# RK3399-AP register map
File version: 1
CPU: CA7 r0p1, little endian, MPU, FPU, I-cache, D-cache, VTOR, 4 interrupt priority bits, 0 interrupts
Registers are 32-bit, read-write, reset 0x0 unless marked. A register's access mark holds for its fields unless they carry their own. Offsets are from the block's base; [hi:lo] are bit positions; <NAME> marks a mode.

## GMAC (part 1 of 2)
Base 0xFE300000
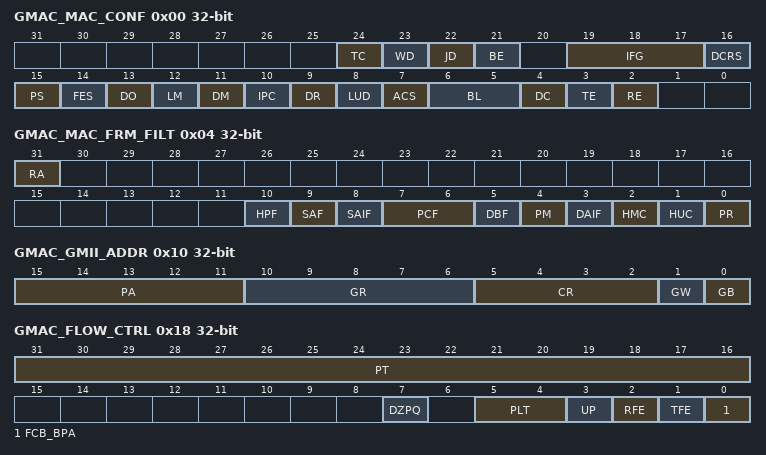
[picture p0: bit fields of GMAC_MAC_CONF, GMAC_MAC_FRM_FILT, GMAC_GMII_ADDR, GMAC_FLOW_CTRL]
0x00 GMAC_MAC_CONF — MAC Configuration Register
  [24] TC — Transmit Configuration in RGMII When set, this bit enables the transmission of duplex mode, link speed, and link up/down information to the PHY in the RGMII ports. When this bit is reset, no such information is driven to the PHY.
  [23] WD — Watchdog Disable When this bit is set, the GMAC disables the watchdog timer on the receiver, and can receive frames of up to 16,384 bytes. When this bit is reset, the GMAC allows no more than 2,048 bytes (10,240 if JE is set high) of the frame being received and cuts off any bytes received after that.
  [22] JD — Jabber Disable When this bit is set, the GMAC disables the jabber timer on the transmitter, and can transfer frames of up to 16,384 bytes. When this bit is reset, the GMAC cuts off the transmitter if the application sends out more than 2,048 bytes of data (10,240 if JE is set high) during transmission.
  [21] BE — Frame Burst Enable When this bit is set, the GMAC allows frame bursting during transmission in GMII Half-Duplex mode.
  [19:17] IFG — Inter-Frame Gap These bits control the minimum IFG between frames during transmission. 3\'b000: 96 bit times 3\'b001: 88 bit times 3\'b010: 80 bit times ... 3\'b111: 40 bit times
  [16] DCRS — Disable Carrier Sense During Transmission When set high, this bit makes the MAC transmitter ignore the (G)MII CRS signal during frame transmission in Half-Duplex mode. This request results in no errors generated due to Loss of Carrier or No Carrier during such transmission. When this bit is low, the MAC transmitter generates such errors due to Carrier Sense and will even abort the transmissions.
  [15] PS — Port Select Selects between GMII and MII: 1\'b0: GMII (1000 Mbps) 1\'b1: MII (10/100 Mbps)
  [14] FES — Speed Indicates the speed in Fast Ethernet (MII) mode: 1\'b0: 10 Mbps 1\'b1: 100 Mbps
  [13] DO — Disable Receive Own When this bit is set, the GMAC disables the reception of frames when the gmii_txen_o is asserted in Half-Duplex mode. When this bit is reset, the GMAC receives all packets that are given by the PHY while transmitting.
  [12] LM — Loopback Mode When this bit is set, the GMAC operates in loopback mode at GMII/MII. The (G)MII Receive clock input (clk_rx_i) is required for the loopback to work properly, as the Transmit clock is not looped-back internally.
  [11] DM — Duplex Mode When this bit is set, the GMAC operates in a Full-Duplex mode where it can transmit and receive simultaneously. This bit is RO with default value of 1\'b1 in Full-Duplex-only configuration.
  [10] IPC — Checksum Offload When this bit is set, the GMAC calculates the 16-bit one\'s complement of the one\'s complement sum of all received Ethernet frame payloads. It also checks whether the IPv4 Header checksum (assumed to be bytes 25-26 or 29-30 (VLAN-tagged) of the received Ethernet frame) is correct for the received frame and gives the status in the receive status word. The GMAC core also appends the 16-bit checksum calculated for the IP header datagram payload (bytes after the IPv4 header) and appends it to the Ethernet frame transferred to the application (when Type 2 COE is deselected). When this bit is reset, this function is disabled. When Type 2 COE is selected, this bit, when set, enables IPv4 checksum checking for received frame payloads TCP/UDP/ICMP headers. When this bit is reset, the COE function in the receiver is disabled and the corresponding PCE and IP HCE status bits are always cleared.
  [9] DR — Disable Retry When this bit is set, the GMAC will attempt only 1 transmission. When a collision occurs on the GMII/MII, the GMAC will ignore the current frame transmission and report a Frame Abort with excessive collision error in the transmit frame status. When this bit is reset, the GMAC will attempt retries based on the settings of BL.
  [8] LUD — Link Up/Down Indicates whether the link is up or down during the transmission of configuration in RGMII interface: 1\'b0: Link Down 1\'b1: Link Up
  [7] ACS — Automatic Pad/CRC Stripping When this bit is set, the GMAC strips the Pad/FCS field on incoming frames only if the length\'s field value is less than or equal to 1,500 bytes. All received frames with length field greater than or equal to 1,501 bytes are passed to the application without stripping the Pad/FCS field. When this bit is reset, the GMAC will pass all incoming frames to the Host unmodified.
  [6:5] BL — Back-Off Limit The Back-Off limit determines the random integer number (r) of slot time delays (4,096 bit times for 1000 Mbps and 512 bit times for 10/100 Mbps) the GMAC waits before rescheduling a transmission attempt during retries after a collision. This bit is applicable only to Half-Duplex mode and is reserved (RO) in Full- Duplex-only configuration. 2\'b00: k = min (n, 10) 2\'b01: k = min (n, 8) 2\'b10: k = min (n, 4) 2\'b11: k = min (n, 1), Where n = retransmission attempt. The random integer r takes the value in the range 0 = r < 2^k
  [4] DC — Deferral Check When this bit is set, the deferral check function is enabled in the GMAC. The GMAC will issue a Frame Abort status, along with the excessive deferral error bit set in the transmit frame status when the transmission state machine is deferred for more than 24,288 bit times in 10/100-Mbps mode. If the Core is configured for 1000 Mbps operation, the threshold for deferral is 155,680 bits times. Deferral begins when the transmitter is ready to transmit, but is prevented because of an active CRS (carrier sense) signal on the GMII/MII. Defer time is not cumulative. If the transmitter defers for 10,000 bit times, then transmits, collides, backs off, and then has to defer again after completion of back-off, the deferral timer resets to 0 and restarts. When this bit is reset, the deferral check function is disabled and the GMAC defers until the CRS signal goes inactive.
  [3] TE — Transmitter Enable When this bit is set, the transmission state machine of the GMAC is enabled for transmission on the GMII/MII. When this bit is reset, the GMAC transmit state machine is disabled after the completion of the transmission of the current frame, and will not transmit any further frames.
  [2] RE — Receiver Enable When this bit is set, the receiver state machine of the GMAC is enabled for receiving frames from the GMII/MII. When this bit is reset, the GMAC receive state machine is disabled after the completion of the reception of the current frame, and will not receive any further frames from the GMII/MII.
0x04 GMAC_MAC_FRM_FILT — MAC Frame Filter
  [31] RA — Receive All When this bit is set, the GMAC Receiver module passes to the Application all frames received irrespective of whether they pass the address filter. The result of the SA/DA filtering is updated (pass or fail) in the corresponding bits in the Receive Status Word. When this bit is reset, the Receiver module passes to the Application only those frames that pass the SA/DA address filter.
  [10] HPF — Hash or Perfect Filter When set, this bit configures the address filter to pass a frame if it matches either the perfect filtering or the hash filtering as set by HMC or HUC bits. When low and if the HUC/HMC bit is set, the frame is passed only if it matches the Hash filter.
  [9] SAF — Source Address Filter Enable The GMAC core compares the SA field of the received frames with the values programmed in the enabled SA registers. If the comparison matches, then the SAMatch bit of RxStatus Word is set high. When this bit is set high and the SA filter fails, the GMAC drops the frame. When this bit is reset, then the GMAC Core forwards the received frame to the application and with the updated SA Match bit of the RxStatus depending on the SA address comparison.
  [8] SAIF — SA Inverse Filtering When this bit is set, the Address Check block operates in inverse filtering mode for the SA address comparison. The frames whose SA matches the SA registers will be marked as failing the SA Address filter. When this bit is reset, frames whose SA does not match the SA registers will be marked as failing the SA Address filter.
  [7:6] PCF — Pass Control Frames These bits control the forwarding of all control frames (including unicast and multicast PAUSE frames). Note that the processing of PAUSE control frames depends only on RFE of Register GMAC_FLOW_CTRL[2]. 2\'b00: GMAC filters all control frames from reaching the application. 2\'b01: GMAC forwards all control frames except PAUSE control frames to application even if they fail the Address filter. 2\'b10: GMAC forwards all control frames to application even if they fail the Address Filter. 2\'b11: GMAC forwards control frames that pass the Address Filter.
  [5] DBF — Disable Broadcast Frames When this bit is set, the AFM module filters all incoming broadcast frames. When this bit is reset, the AFM module passes all received broadcast frames.
  [4] PM — Pass All Multicast When set, this bit indicates that all received frames with a multicast destination address (first bit in the destination address field is \'1\') are passed. When reset, filtering of multicast frame depends on HMC bit.
  [3] DAIF — DA Inverse Filtering When this bit is set, the Address Check block operates in inverse filtering mode for the DA address comparison for both unicast and multicast frames. When reset, normal filtering of frames is performed.
  [2] HMC — Hash Multicast When set, MAC performs destination address filtering of received multicast frames according to the hash table. When reset, the MAC performs a perfect destination address filtering for multicast frames, that is, it compares the DA field with the values programmed in DA registers.
  [1] HUC — Hash Unicast When set, MAC performs destination address filtering of unicast frames according to the hash table. When reset, the MAC performs a perfect destination address filtering for unicast frames, that is, it compares the DA field with the values programmed in DA registers.
  [0] PR — Promiscuous Mode When this bit is set, the Address Filter module passes all incoming frames regardless of its destination or source address. The SA/DA Filter Fails status bits of the Receive Status Word will always be cleared when PR is set.
0x08 GMAC_HASH_TAB_HI — Hash Table High Register
  [31:0] HTH — Hash Table High This field contains the upper 32 bits of Hash table
0x0C GMAC_HASH_TAB_LO — Hash Table Low Register
  [31:0] HTL — Hash Table Low This field contains the lower 32 bits of Hash table
0x10 GMAC_GMII_ADDR — GMII Address Register
  [15:11] PA — Physical Layer Address This field tells which of the 32 possible PHY devices are being accessed
  [10:6] GR — GMII Register These bits select the desired GMII register in the selected PHY device
  [5:2] CR — APB Clock Range The APB Clock Range selection determines the frequency of the MDC clock as per the pclk_gmac frequency used in your design. The suggested range of pclk_gmac frequency applicable for each value below (when Bit[5] = 0) ensures that the MDC clock is approximately between the frequency range 1.0 MHz - 2.5 MHz. 0000 60-100 MHz pclk_gmac/42 0001 100-150 MHz pclk_gmac/62 0010 20-35 MHz pclk_gmac/16 0011 35-60 MHz pclk_gmac/26 0100 150-250 MHz pclk_gmac/102 0101 250-300 MHz pclk_gmac/124 0110, 0111 Reserved When bit 5 is set, you can achieve MDC clock of frequency higher than the IEEE802.3 specified frequency limit of 2.5 MHz and program a clock divider of lower value. For example, when pclk_gmac is of frequency 100 MHz and you program these bits as "1010", then the resultant MDC clock will be of 12.5 MHz which is outside the limit of IEEE 802.3 specified range. Please program the values given below only if the interfacing chips supports faster MDC clocks. 1000 pclk_gmac/4 1001 pclk_gmac/6 1010 pclk_gmac/8 1011 pclk_gmac/10 1100 pclk_gmac/12 1101 pclk_gmac/14 1110 pclk_gmac/16 1111 pclk_gmac/18
  [1] GW — GMII Write When set, this bit tells the PHY that this will be a Write operation using register GMAC_GMII_DATA. If this bit is not set, this will be a Read operation, placing the data in register GMAC_GMII_DATA.
  [0] GB write-1-clears — GMII Busy This bit should read a logic 0 before writing to Register GMII_ADDR and Register GMII_DATA. This bit must also be set to 0 during a Write to Register GMII_ADDR. During a PHY register access, this bit will be set to 1\'b1 by the Application to indicate that a Read or Write access is in progress. Register GMII_DATA (GMII Data) should be kept valid until this bit is cleared by the GMAC during a PHY Write operation. The Register GMII_DATA is invalid until this bit is cleared by the GMAC during a PHY Read operation. The Register GMII_ADDR (GMII Address) should not be written to until this bit is cleared.
0x14 GMAC_GMII_DATA — GMII Data Register
  [15:0] GD — GMII Data This contains the 16-bit data value read from the PHY after a Management Read operation or the 16-bit data value to be written to the PHY before a Management Write operation.
0x18 GMAC_FLOW_CTRL — Flow Control Register
  [31:16] PT — Pause Time This field holds the value to be used in the Pause Time field in the transmit control frame. If the Pause Time bits is configured to be double-synchronized to the (G)MII clock domain, then consecutive writes to this register should be performed only after at least 4 clock cycles in the destination clock domain.
  [7] DZPQ — Disable Zero-Quanta Pause When set, this bit disables the automatic generation of Zero- Quanta Pause Control frames on the de-assertion of the flow- control signal from the FIFO layer (MTL or external sideband flow control signal sbd_flowctrl_i/mti_flowctrl_i). When this bit is reset, normal operation with automatic Zero- Quanta Pause Control frame generation is enabled.
  [5:4] PLT — Pause Low Threshold This field configures the threshold of the PAUSE timer at which the input flow control signal mti_flowctrl_i (or sbd_flowctrl_i) is checked for automatic retransmission of PAUSE Frame. The threshold values should be always less than the Pause Time configured in Bits[31:16]. For example, if PT = 100H (256 slot- times), and PLT = 01, then a second PAUSE frame is automatically transmitted if the mti_flowctrl_i signal is asserted at 228 (256-28) slot-times after the first PAUSE frame is transmitted. 00 Pause time minus 4 slot times 01 Pause time minus 28 slot times 10 Pause time minus 144 slot times 11 Pause time minus 256 slot times Slot time is defined as time taken to transmit 512 bits (64 bytes) on the GMII/MII interface.
  [3] UP — Unicast Pause Frame Detect When this bit is set, the GMAC will detect the Pause frames with the station\'s unicast address specified in MAC Address0 High Register and MAC Address0 Low Register, in addition to the detecting Pause frames with the unique multicast address. When this bit is reset, the GMAC will detect only a Pause frame with the unique multicast address specified in the 802.3x standard.
  [2] RFE — Receive Flow Control Enable When this bit is set, the GMAC will decode the received Pause frame and disable its transmitter for a specified (Pause Time) time. When this bit is reset, the decode function of the Pause frame is disabled.
  [1] TFE — Transmit Flow Control Enable In Full-Duplex mode, when this bit is set, the GMAC enables the flow control operation to transmit Pause frames. When this bit is reset, the flow control operation in the GMAC is disabled, and the GMAC will not transmit any Pause frames. In Half-Duplex mode, when this bit is set, the GMAC enables the back-pressure operation. When this bit is reset, the backpressure feature is disabled.
  [0] FCB_BPA — Flow Control Busy/Backpressure Activate This bit initiates a Pause Control frame in Full-Duplex mode and activates the backpressure function in Half-Duplex mode if TFE bit is set. In Full-Duplex mode, this bit should be read as 1\'b0 before writing to the register GMAC_FLOW_CTRL. To initiate a pause control frame, the application must set this bit to 1\'b1. During a transfer of the control frame, this bit will continue to be set to signify that a frame transmission is in progress. After the completion of Pause control frame transmission, the GMAC will reset this bit to 1\'b0. The register GMAC_FLOW_CTRL should not be written to until this bit is cleared. In Half-Duplex mode, when this bit is set (and TFE is set), then backpressure is asserted by the GMAC Core. During backpressure, when the GMAC receives a new frame, the transmitter starts sending a JAM pattern resulting in a collision. This control register bit is logically OR\'ed with the mti_flowctrl_i input signal for the backpressure function.
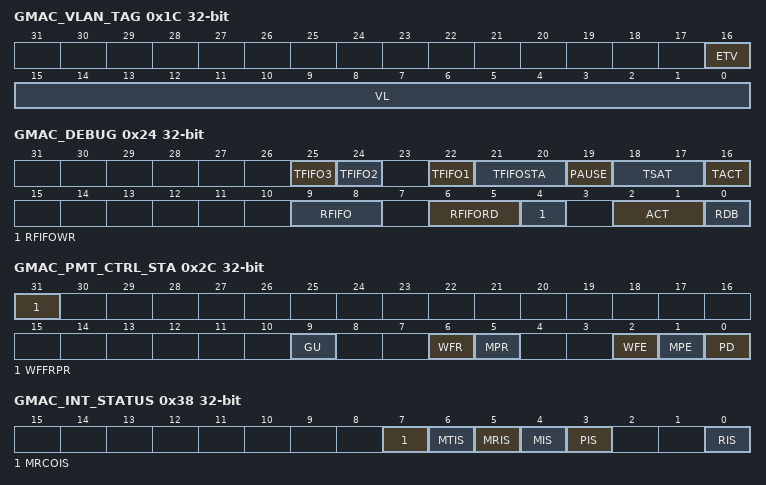
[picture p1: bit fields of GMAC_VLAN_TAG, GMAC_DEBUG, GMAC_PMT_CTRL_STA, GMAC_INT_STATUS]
0x1C GMAC_VLAN_TAG — VLAN Tag Register
  [16] ETV — Enable 12-Bit VLAN Tag Comparison When this bit is set, a 12-bit VLAN identifier, rather than the complete 16-bit VLAN tag, is used for comparison and filtering. Bits[11:0] of the VLAN tag are compared with the corresponding field in the received VLAN-tagged frame. When this bit is reset, all 16 bits of the received VLAN frame\'s fifteenth and sixteenth bytes are used for comparison.
  [15:0] VL — VLAN Tag Identifier for Receive Frames This contains the 802.1Q VLAN tag to identify VLAN frames, and is compared to the fifteenth and sixteenth bytes of the frames being received for VLAN frames. Bits[15:13] are the User Priority, Bit[12] is the Canonical Format Indicator (CFI) and bits[11:0] are the VLAN tag\'s VLAN Identifier (VID) field. When the ETV bit is set, only the VID (Bits[11:0]) is used for comparison. If VL (VL[11:0] if ETV is set) is all zeros, the GMAC does not check the fifteenth and sixteenth bytes for VLAN tag comparison, and declares all frames with a Type field value of 0x8100 to be VLAN frames.
0x24 GMAC_DEBUG — Debug register
  [25] TFIFO3 — When high, it indicates that the MTL TxStatus FIFO is full and hence the MTL will not be accepting any more frames for transmission.
  [24] TFIFO2 — When high, it indicates that the MTL TxFIFO is not empty and has some data left for transmission.
  [22] TFIFO1 — When high, it indicates that the MTL TxFIFO Write Controller is active and transferring data to the TxFIFO.
  [21:20] TFIFOSTA — This indicates the state of the TxFIFO read Controller: 2\'b00: IDLE state 2\'b01: READ state (transferring data to MAC transmitter) 2\'b10: Waiting for TxStatus from MAC transmitter 2\'b11: Writing the received TxStatus or flushing the TxFIFO
  [19] PAUSE — When high, it indicates that the MAC transmitter is in PAUSE condition (in full-duplex only) and hence will not schedule any frame for transmission
  [18:17] TSAT — This indicates the state of the MAC Transmit Frame Controller module: 2\'b00: IDLE 2\'b01: Waiting for Status of previous frame or IFG/backoff period to be over 2\'b10: Generating and transmitting a PAUSE control frame (in full duplex mode) 2\'b11: Transferring input frame for transmission
  [16] TACT — When high, it indicates that the MAC GMII/MII transmit protocol engine is actively transmitting data and not in IDLE state.
  [9:8] RFIFO — This gives the status of the RxFIFO Fill-level: 2\'b00: RxFIFO Empty 2\'b01: RxFIFO fill-level below flow-control de-activate threshold 2\'b10: RxFIFO fill-level above flow-control activate threshold 2\'b11: RxFIFO Full
  [6:5] RFIFORD — It gives the state of the RxFIFO read Controller: 2\'b00: IDLE state 2\'b01: Reading frame data 2\'b10: Reading frame status (or time-stamp) 2\'b11: Flushing the frame data and Status
  [4] RFIFOWR — When high, it indicates that the MTL RxFIFO Write Controller is active and transferring a received frame to the FIFO.
  [2:1] ACT — When high, it indicates the active state of the small FIFO Read and Write controllers respectively of the MAC receive Frame Controller module
  [0] RDB — When high, it indicates that the MAC GMII/MII receive protocol engine is actively receiving data and not in IDLE state.
0x2C GMAC_PMT_CTRL_STA access per field — PMT Control and Status Register
  [31] WFFRPR rw write-1-clears — Wake-Up Frame Filter Register Pointer Reset When set, resets the Remote Wake-up Frame Filter register pointer to 3\'b000. It is automatically cleared after 1 clock cycle.
  [9] GU rw — Global Unicast When set, enables any unicast packet filtered by the GMAC (DAF) address recognition to be a wake-up frame.
  [6] WFR ro read-clears — Wake-Up Frame Received When set, this bit indicates the power management event was generated due to reception of a wake-up frame. This bit is cleared by a read into this register.
  [5] MPR ro read-clears — Magic Packet Received When set, this bit indicates the power management event was generated by the reception of a Magic Packet. This bit is cleared by a read into this register.
  [2] WFE rw — Wake-Up Frame Enable When set, enables generation of a power management event due to wake-up frame reception.
  [1] MPE rw — Magic Packet Enable When set, enables generation of a power management event due to Magic Packet reception.
  [0] PD wo write-clears — Power Down When set, all received frames will be dropped. This bit is cleared automatically when a magic packet or Wake-Up frame is received, and Power-Down mode is disabled. Frames received after this bit is cleared are forwarded to the application. This bit must only be set when either the Magic Packet Enable or Wake- Up Frame Enable bit is set high.
0x38 GMAC_INT_STATUS ro — Interrupt Status Register
  [7] MRCOIS — MMC Receive Checksum Offload Interrupt Status This bit is set high whenever an interrupt is generated in the MMC Receive Checksum Offload Interrupt Register. This bit is cleared when all the bits in this interrupt register are cleared.
  [6] MTIS — MMC Transmit Interrupt Status This bit is set high whenever an interrupt is generated in the MMC Transmit Interrupt Register. This bit is cleared when all the bits in this interrupt register are cleared. This bit is only valid when the optional MMC module is selected during configuration.
  [5] MRIS — MMC Receive Interrupt Status This bit is set high whenever an interrupt is generated in the MMC Receive Interrupt Register. This bit is cleared when all the bits in this interrupt register are cleared. This bit is only valid when the optional MMC module is selected during configuration.
  [4] MIS — MMC Interrupt Status This bit is set high whenever any of bits 7:5 is set high and cleared only when all of these bits are low. This bit is valid only when the optional MMC module is selected during configuration.
  [3] PIS — PMT Interrupt Status This bit is set whenever a Magic packet or Wake-on-LAN frame is received in Power-Down mode). This bit is cleared when both bits[6:5] are cleared due to a read operation to the register GMAC_PMT_CTRL_STA.
  [0] RIS — RGMII Interrupt Status This bit is set due to any change in value of the Link Status of RGMII interface. This bit is cleared when the user makes a read operation the RGMII Status register.
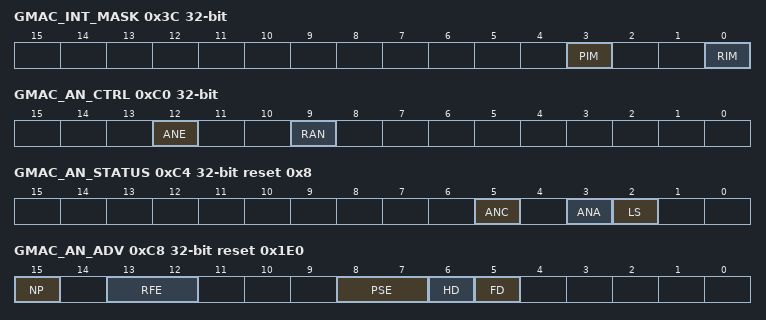
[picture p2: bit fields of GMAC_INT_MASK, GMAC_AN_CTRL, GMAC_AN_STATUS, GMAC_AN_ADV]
0x3C GMAC_INT_MASK — Interrupt Mask Register
  [3] PIM — PMT Interrupt Mask This bit when set, will disable the assertion of the interrupt signal due to the setting of PMT Interrupt Status bit in Register GMAC_INT_STATUS.
  [0] RIM — RGMII Interrupt Mask This bit when set, will disable the assertion of the interrupt signal due to the setting of RGMII Interrupt Status bit in Register GMAC_INT_STATUS.
0x40 GMAC_MAC_ADDR0_HI reset 0xFFFF — MAC Address0 High Register
  [15:0] A47_A32 — MAC Address0 [47:32] This field contains the upper 16 bits (47:32) of the 6-byte first MAC address. This is used by the MAC for filtering for received frames and for inserting the MAC address in the Transmit Flow Control (PAUSE) Frames.
0x44 GMAC_MAC_ADDR0_LO reset 0xFFFFFFFF — MAC Address0 Low Register
  [31:0] A31_A0 — MAC Address0 [31:0] This field contains the lower 32 bits of the 6-byte first MAC address. This is used by the MAC for filtering for received frames and for inserting the MAC address in the Transmit Flow Control (PAUSE) Frames.
0xC0 GMAC_AN_CTRL access per field — AN Control Register
  [12] ANE rw — Auto-Negotiation Enable When set, will enable the GMAC to perform auto-negotiation with the link partner. Clearing this bit will disable auto-negotiation.
  [9] RAN wo write-clears — Restart Auto-Negotiation When set, will cause auto-negotiation to restart if the ANE is set. This bit is self-clearing after auto-negotiation starts. This bit should be cleared for normal operation.
0xC4 GMAC_AN_STATUS access per field reset 0x8 — AN Status Register
  [5] ANC ro — Auto-Negotiation Complete When set, this bit indicates that the auto-negotiation process is completed. This bit is cleared when auto-negotiation is reinitiated.
  [3] ANA ro — Auto-Negotiation Ability This bit is always high, because the GMAC supports auto- negotiation.
  [2] LS wo write-clears — Link Status When set, this bit indicates that the link is up. When cleared, this bit indicates that the link is down.
0xC8 GMAC_AN_ADV access per field reset 0x1E0 — Auto Negotiation Advertisement Register
  [15] NP ro — Next Page Support This bit is tied to low, because the GMAC does not support the next page.
  [13:12] RFE rw — Remote Fault Encoding These 2 bits provide a remote fault encoding, indicating to a link partner that a fault or error condition has occurred.
  [8:7] PSE rw — Pause Encoding These 2 bits provide an encoding for the PAUSE bits, indicating that the GMAC is capable of configuring the PAUSE function as defined in IEEE 802.3x.
  [6] HD rw — Half-Duplex This bit, when set high, indicates that the GMAC supports Half- Duplex. This bit is tied to low (and RO) when the GMAC is configured for Full-Duplex-only operation.
  [5] FD rw — Full-Duplex This bit, when set high, indicates that the GMAC supports Full- Duplex.
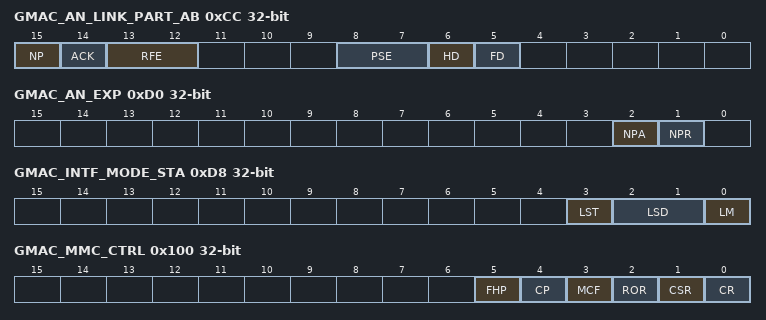
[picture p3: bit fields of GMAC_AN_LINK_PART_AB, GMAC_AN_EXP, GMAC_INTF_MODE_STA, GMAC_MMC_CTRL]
0xCC GMAC_AN_LINK_PART_AB ro — Auto Negotiation Link Partner Ability Register
  [15] NP — Next Page Support When set, this bit indicates that more next page information is available. When cleared, this bit indicates that next page exchange is not desired.
  [14] ACK — Acknowledge When set, this bit is used by the auto-negotiation function to indicate that the link partner has successfully received the GMAC\'s base page. When cleared, it indicates that a successful receipt of the base page has not been achieved.
  [13:12] RFE — Remote Fault Encoding These 2 bits provide a remote fault encoding, indicating a fault or error condition of the link partner.
  [8:7] PSE — Pause Encoding These 2 bits provide an encoding for the PAUSE bits, indicating that the link partner\'s capability of configuring the PAUSE function as defined in IEEE 802.3x.
  [6] HD — Half-Duplex When set, this bit indicates that the link partner has the ability to operate in Half-Duplex mode. When cleared, the link partner does not have the ability to operate in Half-Duplex mode.
  [5] FD — Full-Duplex When set, this bit indicates that the link partner has the ability to operate in Full-Duplex mode. When cleared, the link partner does not have the ability to operate in Full-Duplex mode.
0xD0 GMAC_AN_EXP ro — Auto Negotiation Expansion Register
  [2] NPA — Next Page Ability This bit is tied to low, because the GMAC does not support next page function.
  [1] NPR — New Page Received When set, this bit indicates that a new page has been received by the GMAC. This bit will be cleared when read.
0xD8 GMAC_INTF_MODE_STA access per field — RGMII Status Register
  [3] LST ro — Link Status Indicates whether the link is up (1\'b1) or down (1\'b0)
  [2:1] LSD ro — Link Speed Indicates the current speed of the link: 2\'b00: 2.5 MHz 2\'b01: 25 MHz 2\'b10: 125 MHz
  [0] LM rw — Link Mode Indicates the current mode of operation of the link: 1\'b0: Half-Duplex mode 1\'b1: Full-Duplex mode
0x100 GMAC_MMC_CTRL access per field — MMC Control Register
  [5] FHP rw — Full-Half preset When low and bit4 is set, all MMC counters get preset to almost- half value. All octet counters get preset to 0x7FFF_F800 (half - 2K Bytes) and all frame-counters gets preset to 0x7FFF_FFF0 (half - 16) When high and bit4 is set, all MMC counters get preset to almost- full value. All octet counters get preset to 0xFFFF_F800 (full - 2K Bytes) and all frame-counters gets preset to 0xFFFF_FFF0 (full - 16)
  [4] CP wo write-clears — Counters Preset When set, all counters will be initialized or preset to almost full or almost half as per Bit5 above. This bit will be cleared automatically after 1 clock cycle. This bit along with bit5 is useful for debugging and testing the assertion of interrupts due to MMC counter becoming half-full or full.
  [3] MCF rw — MMC Counter Freeze When set, this bit freezes all the MMC counters to their current value. (None of the MMC counters are updated due to any transmitted or received frame until this bit is reset to 0. If any MMC counter is read with the Reset on Read bit set, then that counter is also cleared in this mode.)
  [2] ROR rw — Reset on Read When set, the MMC counters will be reset to zero after Read (self- clearing after reset). The counters are cleared when the least significant byte lane (bits[7:0]) is read.
  [1] CSR rw — Counter Stop Rollover When set, counter after reaching maximum value will not roll over to zero
  [0] CR wo write-clears — Counters Reset When set, all counters will be reset. This bit will be cleared automatically after 1 clock cycle
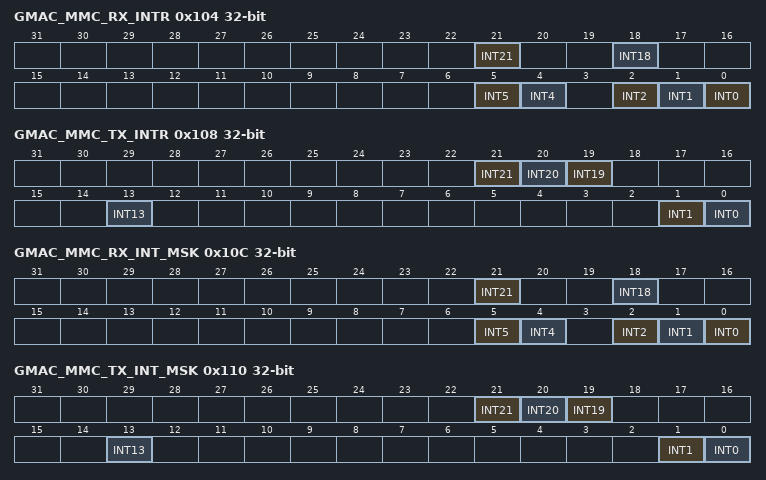
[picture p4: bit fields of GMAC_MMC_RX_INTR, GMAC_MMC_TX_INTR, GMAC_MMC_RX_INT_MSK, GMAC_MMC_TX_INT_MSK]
0x104 GMAC_MMC_RX_INTR access per field — MMC Receive Interrupt Register
  [21] INT21 rw — The bit is set when the rxfifooverflow counter reaches half the maximum value, and also when it reaches the maximum value.
  [18] INT18 ro read-clears — The bit is set when the rxlengtherror counter reaches half the maximum value, and also when it reaches the maximum value.
  [5] INT5 rw — The bit is set when the rxcrcerror counter reaches half the maximum value, and also when it reaches the maximum value.
  [4] INT4 ro read-clears — The bit is set when the rxmulticastframes_g counter reaches half the maximum value, and also when it reaches the maximum value.
  [2] INT2 ro read-clears — The bit is set when the rxoctetcount_g counter reaches half the maximum value, and also when it reaches the maximum value.
  [1] INT1 ro read-clears — The bit is set when the rxoctetcount_gb counter reaches half the maximum value, and also when it reaches the maximum value.
  [0] INT0 ro read-clears — The bit is set when the rxframecount_gb counter reaches half the maximum value, and also when it reaches the maximum value.
0x108 GMAC_MMC_TX_INTR ro — MMC Transmit Interrupt Register
  [21] INT21 read-clears — The bit is set when the txframecount_g counter reaches half the maximum value, and also when it reaches the maximum value.
  [20] INT20 read-clears — The bit is set when the txoctetcount_g counter reaches half the maximum value, and also when it reaches the maximum value.
  [19] INT19 read-clears — The bit is set when the txcarriererror counter reaches half the maximum value, and also when it reaches the maximum value.
  [13] INT13 read-clears — The bit is set when the txunderflowerror counter reaches half the maximum value, and also when it reaches the maximum value.
  [1] INT1 read-clears — The bit is set when the txframecount_gb counter reaches half the maximum value, and also when it reaches the maximum value.
  [0] INT0 read-clears — The bit is set when the txoctetcount_gb counter reaches half the maximum value, and also when it reaches the maximum value.
0x10C GMAC_MMC_RX_INT_MSK — MMC Receive Interrupt Mask Register
  [21] INT21 — Setting this bit masks the interrupt when the rxfifooverflow counter reaches half the maximum value, and also when it reaches the maximum value.
  [18] INT18 — Setting this bit masks the interrupt when the rxlengtherror counter reaches half the maximum value, and also when it reaches the maximum value.
  [5] INT5 — Setting this bit masks the interrupt when the rxcrcerror counter reaches half the maximum value, and also when it reaches the maximum value.
  [4] INT4 — Setting this bit masks the interrupt when the rxmulticastframes_g counter reaches half the maximum value, and also when it reaches the maximum value.
  [2] INT2 — Setting this bit masks the interrupt when the rxoctetcount_g counter reaches half the maximum value, and also when it reaches the maximum value.
  [1] INT1 — Setting this bit masks the interrupt when the rxoctetcount_gb counter reaches half the maximum value, and also when it reaches the maximum value.
  [0] INT0 — Setting this bit masks the interrupt when the rxframecount_gb counter reaches half the maximum value, and also when it reaches the maximum value.
0x110 GMAC_MMC_TX_INT_MSK — MMC Transmit Interrupt Mask Register
  [21] INT21 — Setting this bit masks the interrupt when the txframecount_g counter reaches half the maximum value, and also when it reaches the maximum value.
  [20] INT20 — Setting this bit masks the interrupt when the txoctetcount_g counter reaches half the maximum value, and also when it reaches the maximum value.
  [19] INT19 — Setting this bit masks the interrupt when the txcarriererror counter reaches half the maximum value, and also when it reaches the maximum value.
  [13] INT13 — Setting this bit masks the interrupt when the txunderflowerror counter reaches half the maximum value, and also when it reaches the maximum value.
  [1] INT1 — Setting this bit masks the interrupt when the txframecount_gb counter reaches half the maximum value, and also when it reaches the maximum value.
  [0] INT0 — Setting this bit masks the interrupt when the txoctetcount_gb counter reaches half the maximum value, and also when it reaches the maximum value.
0x114 GMAC_MMC_TXOCTETCNT_GB — MMC TX OCTET Good and Bad Counter
  [31:0] TXOCTETCOUNT_GB — Number of bytes transmitted, exclusive of preamble and retried bytes, in good and bad frames.
0x118 GMAC_MMC_TXFRMCNT_GB — MMC TX Frame Good and Bad Counter
  [31:0] TXFRAMECOUNT_GB — Number of good and bad frames transmitted, exclusive of retried frames.
0x148 GMAC_MMC_TXUNDFLWERR — MMC TX Underflow Error
  [31:0] TXUNDERFLOWERROR — Number of frames aborted due to frame underflow error.
0x160 GMAC_MMC_TXCARERR — MMC TX Carrier Error
  [31:0] TXCARRIERERROR — Number of frames aborted due to carrier sense error (no carrier or loss of carrier).
0x164 GMAC_MMC_TXOCTETCNT_G — MMC TX OCTET Good Counter
  [31:0] TXOCTETCOUNT_G — Number of bytes transmitted, exclusive of preamble, in good frames only.
0x168 GMAC_MMC_TXFRMCNT_G — MMC TX Frame Good Counter
  [31:0] TXFRAMECOUNT_G — Number of good frames transmitted.
0x180 GMAC_MMC_RXFRMCNT_GB — MMC RX Frame Good and Bad Counter
  [31:0] RXFRAMECOUNT_GB — Number of good and bad frames received.
0x184 GMAC_MMC_RXOCTETCNT_GB — MMC RX OCTET Good and Bad Counter
  [31:0] RXOCTETCOUNT_GB — Number of bytes received, exclusive of preamble, in good and bad frames.
0x188 GMAC_MMC_RXOCTETCNT_G — MMC RX OCTET Good Counter
  [31:0] RXOCTETCOUNT_G — Number of bytes received, exclusive of preamble, only in good frames.
